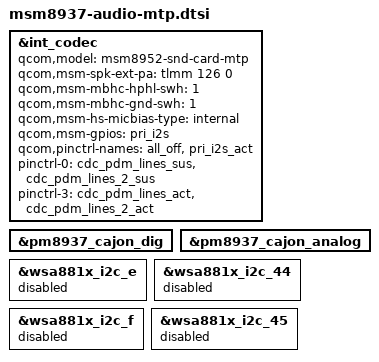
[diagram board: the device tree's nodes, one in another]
/*
 * Copyright (c) 2015, The Linux Foundation. All rights reserved.
 *
 * This program is free software; you can redistribute it and/or modify
 * it under the terms of the GNU General Public License version 2 and
 * only version 2 as published by the Free Software Foundation.
 *
 * This program is distributed in the hope that it will be useful,
 * but WITHOUT ANY WARRANTY; without even the implied warranty of
 * MERCHANTABILITY or FITNESS FOR A PARTICULAR PURPOSE.  See the
 * GNU General Public License for more details.
 */

&int_codec {
	status = "okay";
	qcom,model = "msm8952-snd-card-mtp";
	//++ TN:peter
	qcom,msm-spk-ext-pa = <&tlmm 126 0>;
	qcom,msm-mbhc-hphl-swh = <1>;
	qcom,msm-mbhc-gnd-swh = <1>;
	qcom,msm-hs-micbias-type = "internal";
	qcom,msm-gpios =
		"pri_i2s";
	qcom,pinctrl-names =
		"all_off",
		"pri_i2s_act";
	pinctrl-names =
		"all_off",
		"pri_i2s_act";
	pinctrl-0 = <&cdc_pdm_lines_sus	&cdc_pdm_lines_2_sus>;	
	pinctrl-3 = <&cdc_pdm_lines_act	&cdc_pdm_lines_2_act>;	
	//-- TN:peter
};

&pm8937_cajon_dig {
	status = "okay";
};

&pm8937_cajon_analog {
	status = "okay";
};
//++ TN:peter
&wsa881x_i2c_e {
	status = "disabled";
};

&wsa881x_i2c_44 {
	status = "disabled";
};

&wsa881x_i2c_f {
	status = "disabled";
};

&wsa881x_i2c_45 {
	status = "disabled";
};
//-- TN:peter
